# H6 register map
Vendor: Allwinner; Series: H6; File version: 0.1
CPU: CA53 0, little endian, MPU, no FPU, 0 interrupt priority bits
Registers are 32-bit, read-write, reset 0x0 unless marked. A register's access mark holds for its fields unless they carry their own. Offsets are from the block's base; [hi:lo] are bit positions.

## Thermal_Sensor
Base 0x05070400
0x00 THS_CTRL reset 0x1DF0000 — THS Control Register
  [31:16] SENSOR_ACQ — Sensor acquire time CLK_IN/(N+1)
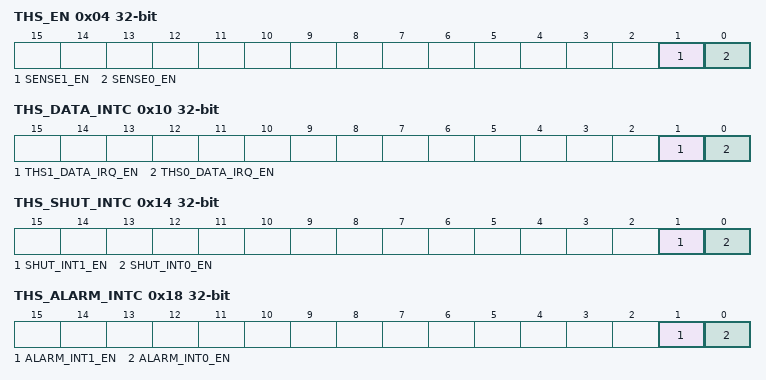
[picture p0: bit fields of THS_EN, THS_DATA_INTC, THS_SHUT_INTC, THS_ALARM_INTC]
0x04 THS_EN — THS Enable Register
  [1] SENSE1_EN — Enable temperature measurement sensor1 0:Disable 1:Enable
  [0] SENSE0_EN — Enable temperature measurement sensor0 0:Disable 1:Enable
0x08 THS_PER reset 0x3A000 — THS Period Control Register
  [31:12] THERMAL_PER — 4096*(n+1)/CLK_IN
0x10 THS_DATA_INTC — THS Data Interrupt Control Register
  [1] THS1_DATA_IRQ_EN — Selects temperature measurement data of sensor1 0:Disable 1:Enable
  [0] THS0_DATA_IRQ_EN — Selects temperature measurement data of sensor0 0:Disable 1:Enable
0x14 THS_SHUT_INTC — THS Shut Interrupt Control Register
  [1] SHUT_INT1_EN — Selects shutdown interrupt for sensor1 0:Disable 1:Enable
  [0] SHUT_INT0_EN — Selects shutdown interrupt for sensor0 0:Disable 1:Enable
0x18 THS_ALARM_INTC — THS Alarm Interrupt Control Register
  [1] ALARM_INT1_EN — Selects alarm interrupt for sensor1 0:Disable 1:Enable
  [0] ALARM_INT0_EN — Selects alarm interrupt for sensor0 0:Disable 1:Enable
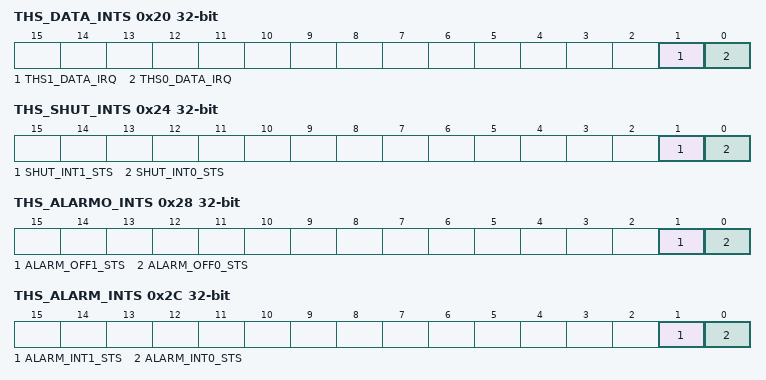
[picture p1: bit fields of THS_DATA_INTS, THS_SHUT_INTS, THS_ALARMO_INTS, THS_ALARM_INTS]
0x20 THS_DATA_INTS — THS Data Interrupt Status Register
  [1] THS1_DATA_IRQ write-1-clears — _STS Data interrupt status for sensor1 Write `1` to clear this interrupt or automatic clear if interrupt condition fails.
  [0] THS0_DATA_IRQ write-1-clears — _STS Data interrupt status for sensor0 Write `1` to clear this interrupt or automatic clear if interrupt condition fails.
0x24 THS_SHUT_INTS — THS Shut Interrupt Status Register
  [1] SHUT_INT1_STS write-1-clears — Shutdown interrupt status for sensor1 Write `1` to clear this interrupt or automatic clear if interrupt condition fails.
  [0] SHUT_INT0_STS write-1-clears — Shutdown interrupt status for sensor0 Write `1` to clear this interrupt or automatic clear if interrupt condition fails
0x28 THS_ALARMO_INTS — THS Alarm off Interrupt Status Register
  [1] ALARM_OFF1_STS write-1-clears — Alarm interrupt off pending for sensor1 Write `1` to clear this interrupt or automatic clear if interrupt condition fails.
  [0] ALARM_OFF0_STS write-1-clears — Alarm interrupt off pending for sensor0 Write `1` to clear this interrupt or automatic clear if interrupt condition fails
0x2C THS_ALARM_INTS — THS Alarm Interrupt Status Register
  [1] ALARM_INT1_STS write-1-clears — Alarm interrupt pending for sensor1 Write `1` to clear this interrupt or automatic clear if interrupt condition fails
  [0] ALARM_INT0_STS write-1-clears — Alarm interrupt pending for sensor0 Write `1` to clear this interrupt or automatic clear if interrupt condition fails
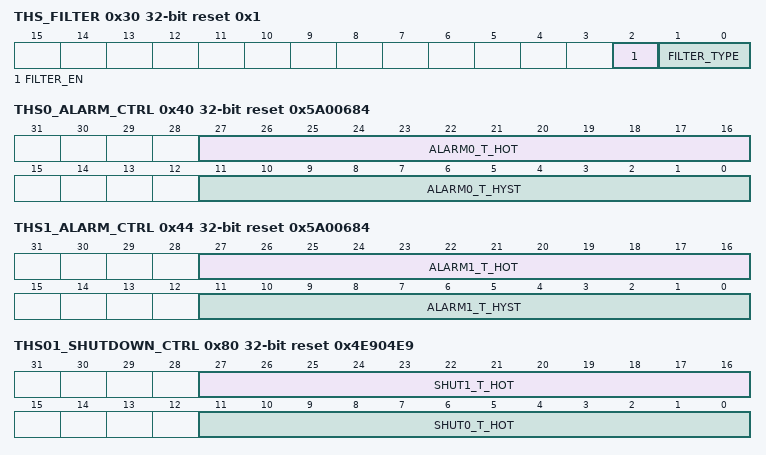
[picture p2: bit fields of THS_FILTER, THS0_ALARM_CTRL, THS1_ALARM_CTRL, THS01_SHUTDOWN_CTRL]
0x30 THS_FILTER reset 0x1 — THS Median Filter Control Register
  [2] FILTER_EN — Filter Enable 0: Disable 1: Enable
    0=Disable; 1=Enable
  [1:0] FILTER_TYPE — Average Filter Type 00: 2 01: 4 10: 8 11: 16
    0=_2; 1=_4; 2=_8; 3=_16
0x40 THS0_ALARM_CTRL reset 0x5A00684 — THS0 Alarm threshold Control Register
  [27:16] ALARM0_T_HOT — Thermal Sensor0 Alarm Threshold for hot temperature
  [11:0] ALARM0_T_HYST — Thermal Sensor0 Alarm threshold for hysteresis temperature
0x44 THS1_ALARM_CTRL reset 0x5A00684 — THS1 Alarm threshold Control Register
  [27:16] ALARM1_T_HOT — Thermal sensor1 Alarm Threshold for hot temperature
  [11:0] ALARM1_T_HYST — Thermal sensor1 Alarm threshold for hysteresis temperature
0x80 THS01_SHUTDOWN_CTRL reset 0x4E904E9 — THS0&1 Alarm threshold Control Register
  [27:16] SHUT1_T_HOT — Thermal Sensor1 Shutdown Threshold for hot temperature
  [11:0] SHUT0_T_HOT — Thermal Sensor0 Shutdown Threshold for hot temperature
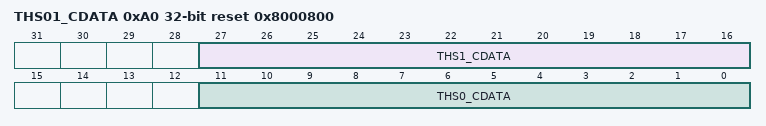
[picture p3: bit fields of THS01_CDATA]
0xA0 THS01_CDATA reset 0x8000800 — THS0&1 Calibration Data
  [27:16] THS1_CDATA — Thermal Sensor1 calibration data
  [11:0] THS0_CDATA — Thermal Sensor0 calibration data
0xC0 THS0_DATA
  [11:0] THS0_DATA ro — Temperature measurement data of sensor0
0xC4 THS1_DATA
  [11:0] THS1_DATA ro — Temperature measurement data of sensor1
